AUTOSAR XML (schema 4-0-3)
standard types defined: Boolean, UInt16
package /AUTOSAR_Platform/DataConstrs
  range DC_Boolean: raw 0..1
  range DC_UInt16: raw 0..65535
package /PATAC/MSM/ComponentTypes
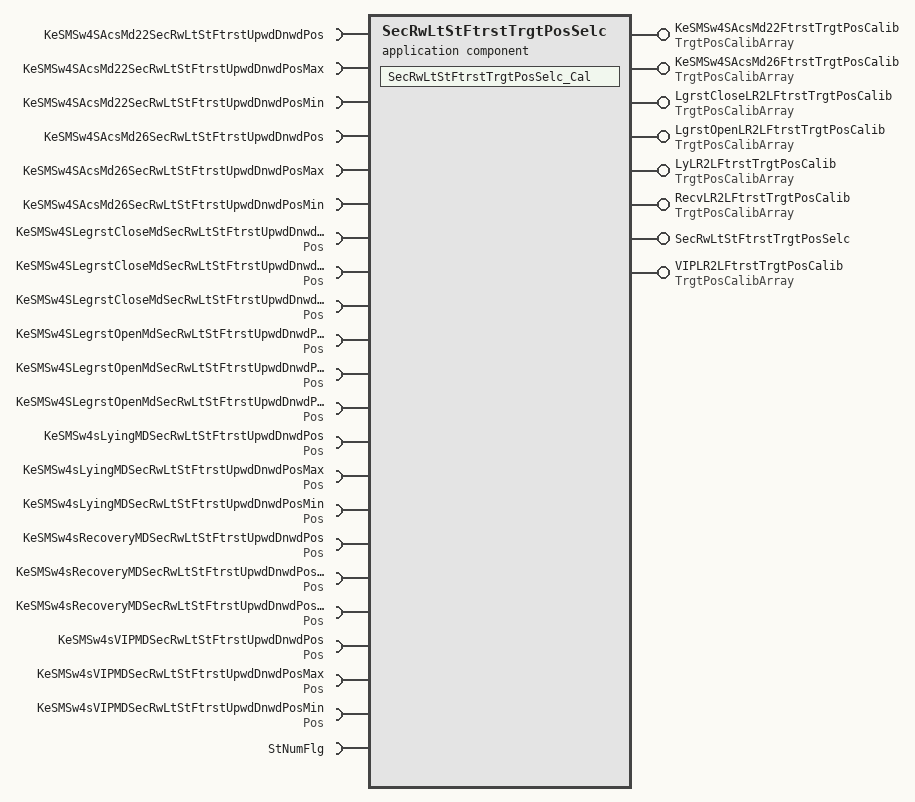
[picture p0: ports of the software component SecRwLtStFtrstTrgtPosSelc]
  application sw component type SecRwLtStFtrstTrgtPosSelc
    8 x provide port:
      KeSMSw4SAcsMd22FtrstTrgtPosCalib: nonqueued-sender-com-spec{data-element=TrgtPosArray, init-value=[4095, 4095, 4095]}, provided-interface=TrgtPosCalibArray
      KeSMSw4SAcsMd26FtrstTrgtPosCalib: nonqueued-sender-com-spec{data-element=TrgtPosArray, init-value=[4095, 4095, 4095]}, provided-interface=TrgtPosCalibArray
      LgrstCloseLR2LFtrstTrgtPosCalib: nonqueued-sender-com-spec{data-element=TrgtPosArray, init-value=[4095, 4095, 4095]}, provided-interface=TrgtPosCalibArray
      LgrstOpenLR2LFtrstTrgtPosCalib: nonqueued-sender-com-spec{data-element=TrgtPosArray, init-value=[4095, 4095, 4095]}, provided-interface=TrgtPosCalibArray
      LyLR2LFtrstTrgtPosCalib: nonqueued-sender-com-spec{data-element=TrgtPosArray, init-value=[4095, 4095, 4095]}, provided-interface=TrgtPosCalibArray
      RecvLR2LFtrstTrgtPosCalib: nonqueued-sender-com-spec{data-element=TrgtPosArray, init-value=[4095, 4095, 4095]}, provided-interface=TrgtPosCalibArray
      SecRwLtStFtrstTrgtPosSelc: server-com-spec{operation=Cal, queue-length=1}, provided-interface=SecRwLtStFtrstTrgtPosSelc
      VIPLR2LFtrstTrgtPosCalib: nonqueued-sender-com-spec{data-element=TrgtPosArray, init-value=[4095, 4095, 4095]}, provided-interface=TrgtPosCalibArray
    22 x require port:
      KeSMSw4SAcsMd22SecRwLtStFtrstUpwdDnwdPos: parameter-require-com-spec{init-value=4095, parameter=KeSMSw4SAcsMd22SecRwLtStFtrstUpwdDnwdPos/Val}, required-interface=KeSMSw4SAcsMd22SecRwLtStFtrstUpwdDnwdPos
      KeSMSw4SAcsMd22SecRwLtStFtrstUpwdDnwdPosMax: parameter-require-com-spec{init-value=0, parameter=KeSMSw4SAcsMd22SecRwLtStFtrstUpwdDnwdPosMax/Val}, required-interface=KeSMSw4SAcsMd22SecRwLtStFtrstUpwdDnwdPosMax
      KeSMSw4SAcsMd22SecRwLtStFtrstUpwdDnwdPosMin: parameter-require-com-spec{init-value=0, parameter=KeSMSw4SAcsMd22SecRwLtStFtrstUpwdDnwdPosMin/Val}, required-interface=KeSMSw4SAcsMd22SecRwLtStFtrstUpwdDnwdPosMin
      KeSMSw4SAcsMd26SecRwLtStFtrstUpwdDnwdPos: parameter-require-com-spec{init-value=4095, parameter=KeSMSw4SAcsMd26SecRwLtStFtrstUpwdDnwdPos/Val}, required-interface=KeSMSw4SAcsMd26SecRwLtStFtrstUpwdDnwdPos
      KeSMSw4SAcsMd26SecRwLtStFtrstUpwdDnwdPosMax: parameter-require-com-spec{init-value=0, parameter=KeSMSw4SAcsMd26SecRwLtStFtrstUpwdDnwdPosMax/Val}, required-interface=KeSMSw4SAcsMd26SecRwLtStFtrstUpwdDnwdPosMax
      KeSMSw4SAcsMd26SecRwLtStFtrstUpwdDnwdPosMin: parameter-require-com-spec{init-value=0, parameter=KeSMSw4SAcsMd26SecRwLtStFtrstUpwdDnwdPosMin/Val}, required-interface=KeSMSw4SAcsMd26SecRwLtStFtrstUpwdDnwdPosMin
      KeSMSw4SLegrstCloseMdSecRwLtStFtrstUpwdDnwdPos: parameter-require-com-spec{init-value=0, parameter=Pos/Val}, required-interface=Pos
      KeSMSw4SLegrstCloseMdSecRwLtStFtrstUpwdDnwdPosMax: parameter-require-com-spec{init-value=0, parameter=Pos/Val}, required-interface=Pos
      KeSMSw4SLegrstCloseMdSecRwLtStFtrstUpwdDnwdPosMin: parameter-require-com-spec{init-value=0, parameter=Pos/Val}, required-interface=Pos
      KeSMSw4SLegrstOpenMdSecRwLtStFtrstUpwdDnwdPos: parameter-require-com-spec{init-value=0, parameter=Pos/Val}, required-interface=Pos
      KeSMSw4SLegrstOpenMdSecRwLtStFtrstUpwdDnwdPosMax: parameter-require-com-spec{init-value=0, parameter=Pos/Val}, required-interface=Pos
      KeSMSw4SLegrstOpenMdSecRwLtStFtrstUpwdDnwdPosMin: parameter-require-com-spec{init-value=0, parameter=Pos/Val}, required-interface=Pos
      KeSMSw4sLyingMDSecRwLtStFtrstUpwdDnwdPos: parameter-require-com-spec{init-value=0, parameter=Pos/Val}, required-interface=Pos
      KeSMSw4sLyingMDSecRwLtStFtrstUpwdDnwdPosMax: parameter-require-com-spec{init-value=0, parameter=Pos/Val}, required-interface=Pos
      KeSMSw4sLyingMDSecRwLtStFtrstUpwdDnwdPosMin: parameter-require-com-spec{init-value=0, parameter=Pos/Val}, required-interface=Pos
      KeSMSw4sRecoveryMDSecRwLtStFtrstUpwdDnwdPos: parameter-require-com-spec{init-value=0, parameter=Pos/Val}, required-interface=Pos
      KeSMSw4sRecoveryMDSecRwLtStFtrstUpwdDnwdPosMax: parameter-require-com-spec{init-value=0, parameter=Pos/Val}, required-interface=Pos
      KeSMSw4sRecoveryMDSecRwLtStFtrstUpwdDnwdPosMin: parameter-require-com-spec{init-value=0, parameter=Pos/Val}, required-interface=Pos
      KeSMSw4sVIPMDSecRwLtStFtrstUpwdDnwdPos: parameter-require-com-spec{init-value=0, parameter=Pos/Val}, required-interface=Pos
      KeSMSw4sVIPMDSecRwLtStFtrstUpwdDnwdPosMax: parameter-require-com-spec{init-value=0, parameter=Pos/Val}, required-interface=Pos
      KeSMSw4sVIPMDSecRwLtStFtrstUpwdDnwdPosMin: parameter-require-com-spec{init-value=0, parameter=Pos/Val}, required-interface=Pos
      StNumFlg: required-interface=StNumFlg
        required-com-specs:
          data-element=Is4s, filter=data-filter-type=ALWAYS, init-value=0
          data-element=Is6s, filter=data-filter-type=ALWAYS, init-value=0
          data-element=Is6s7s, filter=data-filter-type=ALWAYS, init-value=0
          data-element=Is7s, filter=data-filter-type=ALWAYS, init-value=0
    behavior SecRwLtStFtrstTrgtPosSelc_InternalBehavior
      operation invoked event OIT_SecRwLtStFtrstTrgtPosSelc_Cal_SecRwLtStFtrstTrgtPosSelc_Cal: start-on-event=SecRwLtStFtrstTrgtPosSelc_Cal, operation=SecRwLtStFtrstTrgtPosSelc.Cal
      runnable SecRwLtStFtrstTrgtPosSelc_Cal
        data-receive-point-by-arguments:
          4 x access:
            REC_StNumFlg_Is4s: accessed-variable=StNumFlg.Is4s
            REC_StNumFlg_Is6s: accessed-variable=StNumFlg.Is6s
            REC_StNumFlg_Is6s7s: accessed-variable=StNumFlg.Is6s7s
            REC_StNumFlg_Is7s: accessed-variable=StNumFlg.Is7s
        data-send-points:
          7 x access:
            SEND_KeSMSw4SAcsMd22FtrstTrgtPosCalib_TrgtPosArray: accessed-variable=KeSMSw4SAcsMd22FtrstTrgtPosCalib.TrgtPosArray
            SEND_KeSMSw4SAcsMd26FtrstTrgtPosCalib_TrgtPosArray: accessed-variable=KeSMSw4SAcsMd26FtrstTrgtPosCalib.TrgtPosArray
            SEND_LgrstCloseLR2LFtrstTrgtPosCalib_TrgtPosArray: accessed-variable=LgrstCloseLR2LFtrstTrgtPosCalib.TrgtPosArray
            SEND_LgrstOpenLR2LFtrstTrgtPosCalib_TrgtPosArray: accessed-variable=LgrstOpenLR2LFtrstTrgtPosCalib.TrgtPosArray
            SEND_LyLR2LFtrstTrgtPosCalib_TrgtPosArray: accessed-variable=LyLR2LFtrstTrgtPosCalib.TrgtPosArray
            SEND_RecvLR2LFtrstTrgtPosCalib_TrgtPosArray: accessed-variable=RecvLR2LFtrstTrgtPosCalib.TrgtPosArray
            SEND_VIPLR2LFtrstTrgtPosCalib_TrgtPosArray: accessed-variable=VIPLR2LFtrstTrgtPosCalib.TrgtPosArray
        21 x parameter access:
          PA_KeSMSw4SAcsMd22SecRwLtStFtrstUpwdDnwdPos_Val: accessed-parameter=KeSMSw4SAcsMd22SecRwLtStFtrstUpwdDnwdPos.Val
          PA_KeSMSw4SAcsMd22SecRwLtStFtrstUpwdDnwdPosMax_Val: accessed-parameter=KeSMSw4SAcsMd22SecRwLtStFtrstUpwdDnwdPosMax.Val
          PA_KeSMSw4SAcsMd22SecRwLtStFtrstUpwdDnwdPosMin_Val: accessed-parameter=KeSMSw4SAcsMd22SecRwLtStFtrstUpwdDnwdPosMin.Val
          PA_KeSMSw4SAcsMd26SecRwLtStFtrstUpwdDnwdPos_Val: accessed-parameter=KeSMSw4SAcsMd26SecRwLtStFtrstUpwdDnwdPos.Val
          PA_KeSMSw4SAcsMd26SecRwLtStFtrstUpwdDnwdPosMax_Val: accessed-parameter=KeSMSw4SAcsMd26SecRwLtStFtrstUpwdDnwdPosMax.Val
          PA_KeSMSw4SAcsMd26SecRwLtStFtrstUpwdDnwdPosMin_Val: accessed-parameter=KeSMSw4SAcsMd26SecRwLtStFtrstUpwdDnwdPosMin.Val
          PA_KeSMSw4SLegrstCloseMdSecRwLtStFtrstUpwdDnwdPos_Val: accessed-parameter=KeSMSw4SLegrstCloseMdSecRwLtStFtrstUpwdDnwdPos.Val
          PA_KeSMSw4SLegrstCloseMdSecRwLtStFtrstUpwdDnwdPosMax_Val: accessed-parameter=KeSMSw4SLegrstCloseMdSecRwLtStFtrstUpwdDnwdPosMax.Val
          PA_KeSMSw4SLegrstCloseMdSecRwLtStFtrstUpwdDnwdPosMin_Val: accessed-parameter=KeSMSw4SLegrstCloseMdSecRwLtStFtrstUpwdDnwdPosMin.Val
          PA_KeSMSw4SLegrstOpenMdSecRwLtStFtrstUpwdDnwdPos_Val: accessed-parameter=KeSMSw4SLegrstOpenMdSecRwLtStFtrstUpwdDnwdPos.Val
          PA_KeSMSw4SLegrstOpenMdSecRwLtStFtrstUpwdDnwdPosMax_Val: accessed-parameter=KeSMSw4SLegrstOpenMdSecRwLtStFtrstUpwdDnwdPosMax.Val
          PA_KeSMSw4SLegrstOpenMdSecRwLtStFtrstUpwdDnwdPosMin_Val: accessed-parameter=KeSMSw4SLegrstOpenMdSecRwLtStFtrstUpwdDnwdPosMin.Val
          PA_KeSMSw4sLyingMDSecRwLtStFtrstUpwdDnwdPos_Val: accessed-parameter=KeSMSw4sLyingMDSecRwLtStFtrstUpwdDnwdPos.Val
          PA_KeSMSw4sLyingMDSecRwLtStFtrstUpwdDnwdPosMax_Val: accessed-parameter=KeSMSw4sLyingMDSecRwLtStFtrstUpwdDnwdPosMax.Val
          PA_KeSMSw4sLyingMDSecRwLtStFtrstUpwdDnwdPosMin_Val: accessed-parameter=KeSMSw4sLyingMDSecRwLtStFtrstUpwdDnwdPosMin.Val
          PA_KeSMSw4sRecoveryMDSecRwLtStFtrstUpwdDnwdPos_Val: accessed-parameter=KeSMSw4sRecoveryMDSecRwLtStFtrstUpwdDnwdPos.Val
          PA_KeSMSw4sRecoveryMDSecRwLtStFtrstUpwdDnwdPosMax_Val: accessed-parameter=KeSMSw4sRecoveryMDSecRwLtStFtrstUpwdDnwdPosMax.Val
          PA_KeSMSw4sRecoveryMDSecRwLtStFtrstUpwdDnwdPosMin_Val: accessed-parameter=KeSMSw4sRecoveryMDSecRwLtStFtrstUpwdDnwdPosMin.Val
          PA_KeSMSw4sVIPMDSecRwLtStFtrstUpwdDnwdPos_Val: accessed-parameter=KeSMSw4sVIPMDSecRwLtStFtrstUpwdDnwdPos.Val
          PA_KeSMSw4sVIPMDSecRwLtStFtrstUpwdDnwdPosMax_Val: accessed-parameter=KeSMSw4sVIPMDSecRwLtStFtrstUpwdDnwdPosMax.Val
          PA_KeSMSw4sVIPMDSecRwLtStFtrstUpwdDnwdPosMin_Val: accessed-parameter=KeSMSw4sVIPMDSecRwLtStFtrstUpwdDnwdPosMin.Val
  swc implementation SecRwLtStFtrstTrgtPosSelc_Implementation: behavior=SecRwLtStFtrstTrgtPosSelc_InternalBehavior
    code-descriptors:
      code Default: artifact-descriptors=autosar-engineering-object={short-label=Default, category=SWSRC}
package /PATAC/MSM/ModeAdjust/CalPortInterface
  7 x parameter interface:
    KeSMSw4SAcsMd22SecRwLtStFtrstUpwdDnwdPos
      parameter data prototype Val: sw-calibration-access=READ-WRITE, type=UInt16
    KeSMSw4SAcsMd22SecRwLtStFtrstUpwdDnwdPosMax
      parameter data prototype Val: sw-calibration-access=READ-WRITE, type=UInt16
    KeSMSw4SAcsMd22SecRwLtStFtrstUpwdDnwdPosMin
      parameter data prototype Val: sw-calibration-access=READ-WRITE, type=UInt16
    KeSMSw4SAcsMd26SecRwLtStFtrstUpwdDnwdPos
      parameter data prototype Val: sw-calibration-access=READ-WRITE, type=UInt16
    KeSMSw4SAcsMd26SecRwLtStFtrstUpwdDnwdPosMax
      parameter data prototype Val: sw-calibration-access=READ-WRITE, type=UInt16
    KeSMSw4SAcsMd26SecRwLtStFtrstUpwdDnwdPosMin
      parameter data prototype Val: sw-calibration-access=READ-WRITE, type=UInt16
    Pos
      parameter data prototype Val: sw-calibration-access=READ-WRITE, type=UInt16
package /PATAC/MSM/ModeAdjust/DataType
  impl type TrgtPosCalibArray: category=ARRAY, sw-calibration-access=READ-ONLY, type-emitter=RTE  # 0:pos 1:max 2:min
    element Element: array-size=3, array-size-semantics=FIXED-SIZE, implementation-data-type=UInt16, invalid-value=0
package /PATAC/MSM/ModeAdjust/PortInterface
  client server interface SecRwLtStFtrstTrgtPosSelc
    operation Cal
  sender receiver interface StNumFlg
    4 x data, all with type=Boolean:
      Is4s
      Is6s
      Is6s7s
      Is7s
    invalidation-policys:
      data-element=Is7s, handle-invalid=DONT-INVALIDATE
      data-element=Is6s, handle-invalid=DONT-INVALIDATE
      data-element=Is4s, handle-invalid=DONT-INVALIDATE
      data-element=Is6s7s, handle-invalid=DONT-INVALIDATE
  sender receiver interface TrgtPosCalibArray: invalidation-policy{data-element=TrgtPosArray, handle-invalid=DONT-INVALIDATE}
    data TrgtPosArray: type=TrgtPosCalibArray  # 0:Pos 1:Max 2:Min
